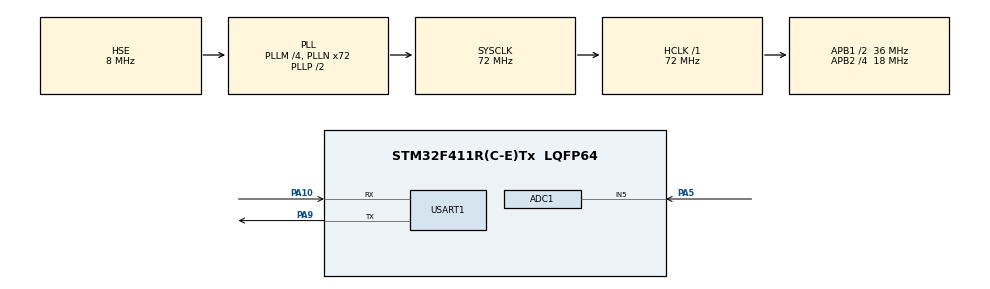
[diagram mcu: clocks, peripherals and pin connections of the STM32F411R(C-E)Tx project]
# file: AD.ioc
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ADC1.Channel-0\#ChannelRegularConversion=ADC_CHANNEL_5
ADC1.ClockPrescaler=ADC_CLOCK_SYNC_PCLK_DIV2
ADC1.ContinuousConvMode=ENABLE
ADC1.NbrOfConversionFlag=1
ADC1.Rank-0\#ChannelRegularConversion=1
ADC1.SamplingTime-0\#ChannelRegularConversion=ADC_SAMPLETIME_15CYCLES
ADC1.master=1
Mcu.Family=STM32F4
Mcu.Name=STM32F411R(C-E)Tx
Mcu.Package=LQFP64
NVIC.ADC_IRQn=true\:0\:0\:false\:false\:true\:true\:true
NVIC.PriorityGroup=NVIC_PRIORITYGROUP_4
NVIC.USART1_IRQn=true\:0\:0\:false\:false\:true\:true\:true
PA10.Mode=Asynchronous
PA10.Signal=USART1_RX
PA5.Signal=ADCx_IN5
PA9.Mode=Asynchronous
PA9.Signal=USART1_TX
PC14-OSC32_IN.Mode=LSE-External-Oscillator
PC14-OSC32_IN.Signal=RCC_OSC32_IN
PC15-OSC32_OUT.Mode=LSE-External-Oscillator
PC15-OSC32_OUT.Signal=RCC_OSC32_OUT
PH0\ -\ OSC_IN.Mode=HSE-External-Oscillator
PH0\ -\ OSC_IN.Signal=RCC_OSC_IN
PH1\ -\ OSC_OUT.Mode=HSE-External-Oscillator
PH1\ -\ OSC_OUT.Signal=RCC_OSC_OUT
ProjectManager.HeapSize=0x200
ProjectManager.StackSize=0x400
ProjectManager.TargetToolchain=MDK-ARM V5
RCC.48MHZClocksFreq_Value=36000000
RCC.AHBFreq_Value=72000000
RCC.APB1CLKDivider=RCC_HCLK_DIV2
RCC.APB1Freq_Value=36000000
RCC.APB1TimFreq_Value=72000000
RCC.APB2CLKDivider=RCC_HCLK_DIV4
RCC.APB2Freq_Value=18000000
RCC.APB2TimFreq_Value=36000000
RCC.CortexFreq_Value=72000000
RCC.HCLKFreq_Value=72000000
RCC.HSE_VALUE=8000000
RCC.HSI_VALUE=16000000
RCC.PLLM=4
RCC.PLLN=72
RCC.PLLSourceVirtual=RCC_PLLSOURCE_HSE
RCC.SYSCLKFreq_VALUE=72000000
RCC.SYSCLKSource=RCC_SYSCLKSOURCE_PLLCLK
RCC.VCOOutputFreq_Value=144000000
SH.ADCx_IN5.0=ADC1_IN5,IN5
USART1.VirtualMode=VM_ASYNC
board=custom

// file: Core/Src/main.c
/* USER CODE BEGIN Header */
/**
  ******************************************************************************
  * @file           : main.c
  * @brief          : Main program body
  ******************************************************************************
  * @attention
  *
  * <h2><center>&copy; Copyright (c) 2023 STMicroelectronics.
  * All rights reserved.</center></h2>
  *
  * This software component is licensed by ST under BSD 3-Clause license,
  * the "License"; You may not use this file except in compliance with the
  * License. You may obtain a copy of the License at:
  *                        opensource.org/licenses/BSD-3-Clause
  *
  ******************************************************************************
  */
/* USER CODE END Header */
#include "main.h"
#include <stdio.h>

ADC_HandleTypeDef hadc1;

UART_HandleTypeDef huart1;

void SystemClock_Config(void);
static void MX_GPIO_Init(void);
static void MX_USART1_UART_Init(void);
static void MX_ADC1_Init(void);

/* USER CODE BEGIN 0 */
int fputc(int ch, FILE *f);
int fgetc(FILE *f);
/* USER CODE END 0 */

int main(void)
{
  /* USER CODE BEGIN 1 */
  unsigned char data[25] = {'s','t','m','i','s','o','k'};
	//printf("stm32 has ready");
	int count = 0;
	uint16_t ADC_Value;
  /* USER CODE END 1 */

  /* MCU Configuration--------------------------------------------------------*/

  /* Reset of all peripherals, Initializes the Flash interface and the Systick. */
  HAL_Init();

  /* Configure the system clock */
  SystemClock_Config();

  /* Initialize all configured peripherals */
  MX_GPIO_Init();
  MX_USART1_UART_Init();
  MX_ADC1_Init();
  /* USER CODE BEGIN 2 */
  //printf("\nstm32 has ready");
  /* USER CODE END 2 */
   //unsigned char data[20] = {'o','k'};
	 printf("receive! \n");
	 //HAL_UART_Transmit(&huart1, data,sizeof(data), 1000);
  /* Infinite loop */
  while (1)
  {
      HAL_ADC_Start(&hadc1);     //启动ADC转换
      HAL_ADC_PollForConversion(&hadc1, 50);   //等待转换完成，50为最大等待时间，单位为ms
     if(HAL_IS_BIT_SET(HAL_ADC_GetState(&hadc1), HAL_ADC_STATE_REG_EOC))
     {
         ADC_Value = HAL_ADC_GetValue(&hadc1);   //获取AD值
			   printf("Value = %d \n",ADC_Value);
			   HAL_Delay(2000);

      }
  }
}

void SystemClock_Config(void)
{
  RCC_OscInitTypeDef RCC_OscInitStruct = {0};
  RCC_ClkInitTypeDef RCC_ClkInitStruct = {0};

  /** Configure the main internal regulator output voltage
  */
  __HAL_RCC_PWR_CLK_ENABLE();
  __HAL_PWR_VOLTAGESCALING_CONFIG(PWR_REGULATOR_VOLTAGE_SCALE1);
  /** Initializes the RCC Oscillators according to the specified parameters
  * in the RCC_OscInitTypeDef structure.
  */
  RCC_OscInitStruct.OscillatorType = RCC_OSCILLATORTYPE_HSE;
  RCC_OscInitStruct.HSEState = RCC_HSE_ON;
  RCC_OscInitStruct.PLL.PLLState = RCC_PLL_ON;
  RCC_OscInitStruct.PLL.PLLSource = RCC_PLLSOURCE_HSE;
  RCC_OscInitStruct.PLL.PLLM = 4;
  RCC_OscInitStruct.PLL.PLLN = 72;
  RCC_OscInitStruct.PLL.PLLP = RCC_PLLP_DIV2;
  RCC_OscInitStruct.PLL.PLLQ = 4;
  if (HAL_RCC_OscConfig(&RCC_OscInitStruct) != HAL_OK)
  {
    Error_Handler();
  }
  /** Initializes the CPU, AHB and APB buses clocks
  */
  RCC_ClkInitStruct.ClockType = RCC_CLOCKTYPE_HCLK|RCC_CLOCKTYPE_SYSCLK
                              |RCC_CLOCKTYPE_PCLK1|RCC_CLOCKTYPE_PCLK2;
  RCC_ClkInitStruct.SYSCLKSource = RCC_SYSCLKSOURCE_PLLCLK;
  RCC_ClkInitStruct.AHBCLKDivider = RCC_SYSCLK_DIV1;
  RCC_ClkInitStruct.APB1CLKDivider = RCC_HCLK_DIV2;
  RCC_ClkInitStruct.APB2CLKDivider = RCC_HCLK_DIV4;

  if (HAL_RCC_ClockConfig(&RCC_ClkInitStruct, FLASH_LATENCY_2) != HAL_OK)
  {
    Error_Handler();
  }
}

static void MX_ADC1_Init(void)
{

  ADC_ChannelConfTypeDef sConfig = {0};

  /** Configure the global features of the ADC (Clock, Resolution, Data Alignment and number of conversion)
  */
  hadc1.Instance = ADC1;
  hadc1.Init.ClockPrescaler = ADC_CLOCK_SYNC_PCLK_DIV2;
  hadc1.Init.Resolution = ADC_RESOLUTION_12B;
  hadc1.Init.ScanConvMode = DISABLE;
  hadc1.Init.ContinuousConvMode = ENABLE;
  hadc1.Init.DiscontinuousConvMode = DISABLE;
  hadc1.Init.ExternalTrigConvEdge = ADC_EXTERNALTRIGCONVEDGE_NONE;
  hadc1.Init.ExternalTrigConv = ADC_SOFTWARE_START;
  hadc1.Init.DataAlign = ADC_DATAALIGN_RIGHT;
  hadc1.Init.NbrOfConversion = 1;
  hadc1.Init.DMAContinuousRequests = DISABLE;
  hadc1.Init.EOCSelection = ADC_EOC_SINGLE_CONV;
  if (HAL_ADC_Init(&hadc1) != HAL_OK)
  {
    Error_Handler();
  }
  /** Configure for the selected ADC regular channel its corresponding rank in the sequencer and its sample time.
  */
  sConfig.Channel = ADC_CHANNEL_5;
  sConfig.Rank = 1;
  sConfig.SamplingTime = ADC_SAMPLETIME_15CYCLES;
  if (HAL_ADC_ConfigChannel(&hadc1, &sConfig) != HAL_OK)
  {
    Error_Handler();
  }

}

static void MX_USART1_UART_Init(void)
{

  huart1.Instance = USART1;
  huart1.Init.BaudRate = 115200;
  huart1.Init.WordLength = UART_WORDLENGTH_8B;
  huart1.Init.StopBits = UART_STOPBITS_1;
  huart1.Init.Parity = UART_PARITY_NONE;
  huart1.Init.Mode = UART_MODE_TX_RX;
  huart1.Init.HwFlowCtl = UART_HWCONTROL_NONE;
  huart1.Init.OverSampling = UART_OVERSAMPLING_16;
  if (HAL_UART_Init(&huart1) != HAL_OK)
  {
    Error_Handler();
  }

}

static void MX_GPIO_Init(void)
{

  /* GPIO Ports Clock Enable */
  __HAL_RCC_GPIOC_CLK_ENABLE();
  __HAL_RCC_GPIOH_CLK_ENABLE();
  __HAL_RCC_GPIOA_CLK_ENABLE();

}

/* USER CODE BEGIN 4 */
int fputc(int ch, FILE *f)
{
uint8_t temp[1] = {ch};
HAL_UART_Transmit(&huart1, temp, 1, 2);//huart1需要根据你的配置修改
return ch;
}

int fgetc(FILE *f)
{
  uint8_t ch = 0;
  HAL_UART_Receive(&huart1, &ch, 1, 0xffff);
  return ch;
}

/* USER CODE END 4 */

void Error_Handler(void)
{
  __disable_irq();
  while (1)
  {
  }
}

/************************ (C) COPYRIGHT STMicroelectronics *****END OF FILE****/
